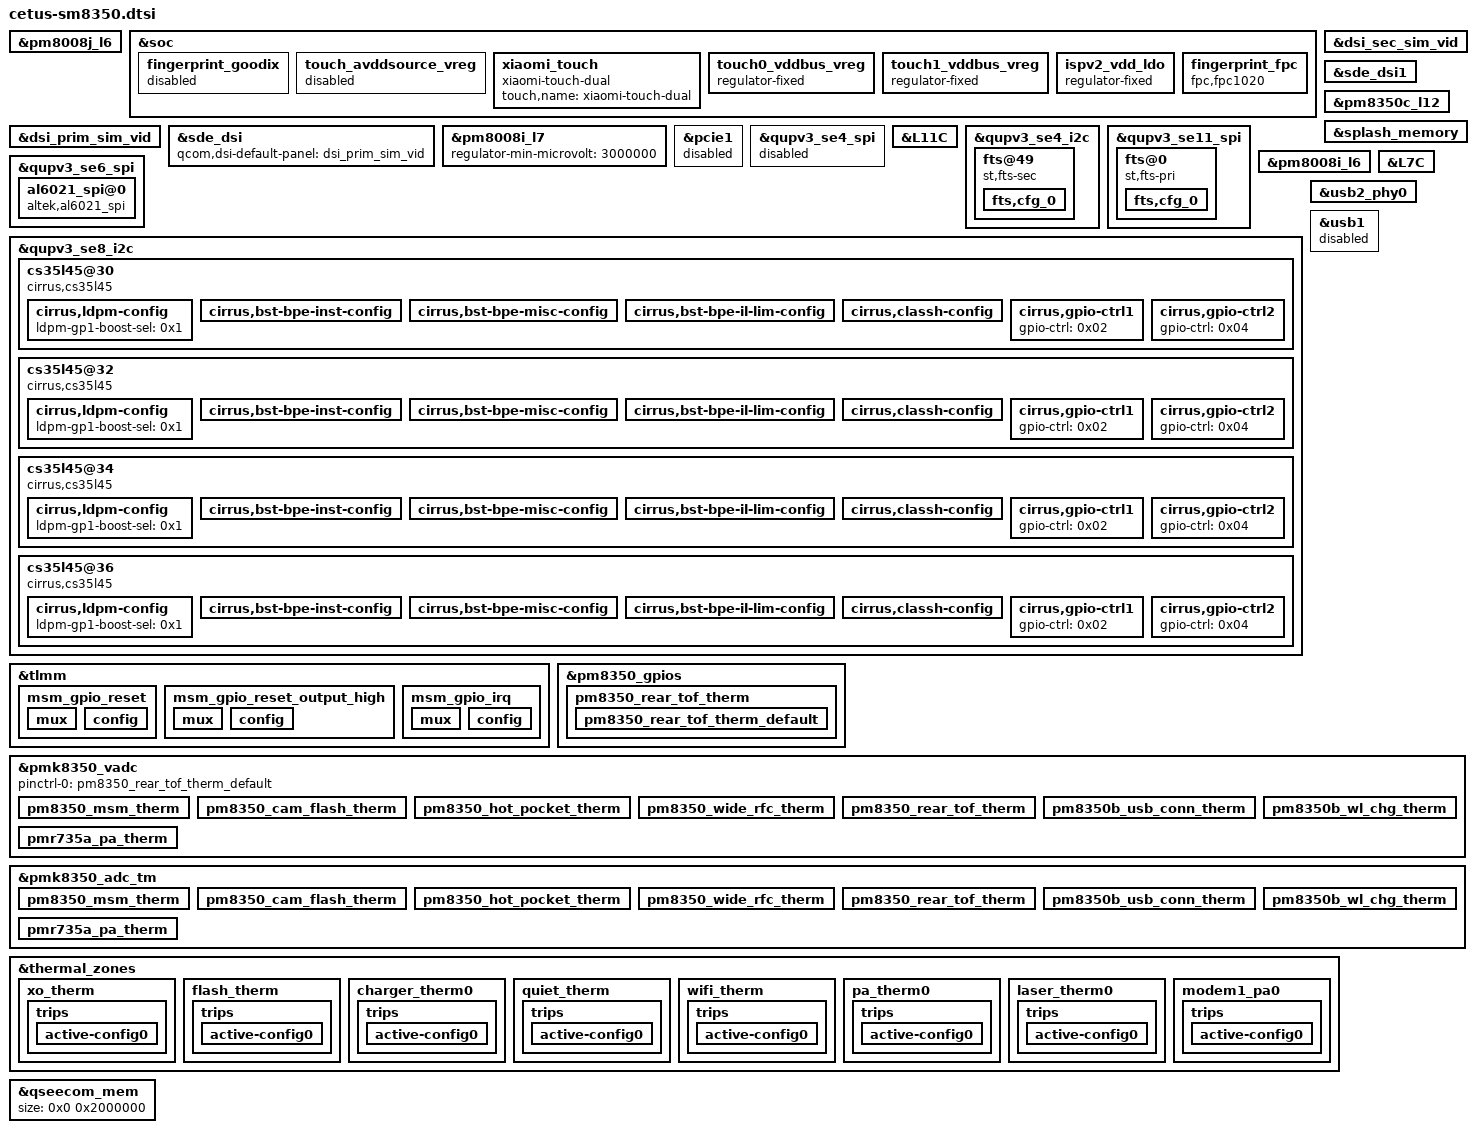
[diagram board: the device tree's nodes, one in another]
/*
this file is for attribution only of star
And public attribution of xiaomi platforms(like venus and so and)
*/

#include "cetus-pinctrl.dtsi"
#include "xiaomi-sm8350-common.dtsi"
#include "cetus-audio-overlay.dtsi"
#include "camera/cetus-sm8350-camera-sensor.dtsi"
#include <dt-bindings/clock/qcom,camcc-lahaina.h>

&pm8008j_l6 {
	reg = <0x4500>;
	regulator-name = "pm8008j_l6";
	regulator-min-microvolt = <1800000>;
	regulator-max-microvolt = <1800000>;
	qcom,min-dropout-voltage = <70000>;
};

&soc {
	fingerprint_goodix {
		status = "disable";
	};

	touch_avddsource_vreg {
		status = "disable";
	};

	xiaomi_touch {
		compatible = "xiaomi-touch-dual";
		status = "ok";
		touch,name = "xiaomi-touch-dual";
	};

	touch0_vddbus_vreg: touch0_vddbus_vreg {
		compatible = "regulator-fixed";
		regulator-name = "touch0_vddbus_vreg";
		enable-active-high;
		regulator-boot-on;
		gpio = <&tlmm 12 0>;
	};

	touch1_vddbus_vreg: touch1_vddbus_vreg {
		compatible = "regulator-fixed";
		regulator-name = "touch1_vddbus_vreg";
		enable-active-high;
		regulator-boot-on;
		gpio = <&tlmm 13 0>;
	};

	ispv2_vdd_ldo: ispv2_vdd_ldo{
		compatible = "regulator-fixed";
		regulator-name = "ispv2_vdd_ldo";
		regulator-min-microvolt = <900000>;
		regulator-max-microvolt = <900000>;
		regulator-enable-ramp-delay = <100>;
		enable-active-high;
		gpio = <&tlmm 166 0>;
		vin-supply = <&pm8350_s11>;
	};

	fingerprint_fpc {
		status = "ok";
		compatible = "fpc,fpc1020";
		interrupt-parent = <&tlmm>;
		interrupts = <38 0x0>;
		fpc,gpio_rst    = <&tlmm 39 0x0>;
		fpc,gpio_irq    = <&tlmm 38 0x0>;
		fpc,gpio_vdd1v8 = <&tlmm 6  0x0>;
		fp_vdd_vreg-supply = <&L7C>;
		pinctrl-names = "fpc1020_reset_reset",
						"fpc1020_reset_active",
						"fpc1020_irq_active";

		pinctrl-0 = <&msm_gpio_reset>;
		pinctrl-1 = <&msm_gpio_reset_output_high>;
		pinctrl-2 = <&msm_gpio_irq>;
	};
};

&dsi_prim_sim_vid {
	qcom,panel-supply-entries = <&dsi_panel_pwr_supply_prim>;
	qcom,mdss-dsi-bl-pmic-control-type = "bl_ctrl_dcs";
	qcom,platform-reset-gpio = <&tlmm 24 0>;
};

&dsi_sec_sim_vid {
	qcom,panel-sec-supply-entries = <&dsi_panel_pwr_supply_sec>;
	qcom,mdss-dsi-sec-bl-pmic-control-type = "bl_ctrl_dcs";
	qcom,platform-sec-reset-gpio = <&tlmm 74 0>;
};

&sde_dsi {
	qcom,dsi-default-panel = <&dsi_prim_sim_vid>;
};

&sde_dsi1 {
	sec-vddio-supply = <&L2C>;
	sec-vdd-supply = <&L7I>;
	qcom,dsi-default-panel = <&dsi_sec_sim_vid>;
};

&pm8008i_l7 {
	regulator-min-microvolt = <3000000>;
};

&pm8350c_l12 {
	regulator-min-microvolt = <1900000>;
	regulator-max-microvolt = <1900000>;
	qcom,init-voltage = <1900000>;
};

&splash_memory {
	reg = <0x0 0xea600000 0x0 0x0119c000>,
		<0x0 0xeb79c000 0x0 0x0815000>;
};

&pcie1 {
	status = "disabled";
};

&qupv3_se4_spi {
	status = "disabled";
};

&L11C {
		regulator-always-on;
		qcom,init-voltage = <3008000>;
};


&qupv3_se4_i2c {
	#address-cells = <1>;
	#size-cells = <0>;

	status = "ok";
	fts@49 {
		status = "ok";
		compatible = "st,fts-sec";
		reg = <0x49>;
		interrupt-parent = <&tlmm>;
		interrupts = <99 0x2008>;
		pinctrl-names = "pmx_ts1_active", "pmx_ts1_suspend";
		pinctrl-0 = <&ts1_active>;
		pinctrl-1 = <&ts1_int_suspend &ts1_reset_suspend>;
		avdd-supply = <&L11C>;
		vdd-supply = <&touch1_vddbus_vreg>;
		fts,pwr-reg-name = "avdd";
		fts,bus-reg-name = "vdd";
		fts,irq-gpio = <&tlmm 99 0x2008>;
		fts,irq-gpio-name = "fts1_irq";
		fts,reset-gpio-enable;
		fts,reset-gpio = <&tlmm 97 0x00>;
		fts,reset-gpio-name = "fts1_rst";
		fts,irq-flags = <0x2008>; /* IRQF_ONESHOT | IRQF_TRIGGER_LOW */
		fts,x-max = <840>;
		fts,y-max = <2520>;
		fts,fod-lx = <421>;
		fts,fod-ly = <1788>;
		fts,fod-x-size = <238>;
		fts,fod-y-size = <238>;
		fts,default-fw-name = "st_fts_j18_sec.ftb";
		fts,config-array-size = <1>;
		/*fts,support-fod;*/
		fts,touch-up-threshold-min = <40>;
		fts,touch-up-threshold-max = <120>;
		fts,touch-up-threshold-def = <80>;
		fts,touch-tolerance-min = <5>;
		fts,touch-tolerance-max = <35>;
		fts,touch-tolerance-def = <25>;
		fts,touch-idletime-min = <0>;
		fts,touch-idletime-max = <12750>;
		fts,touch-idletime-def = <12450>;
		/*edge filter rects in gamemode*/
		fts,cornerfilter-area-step1 = <150>;
		fts,cornerfilter-area-step2 = <280>;
		fts,cornerfilter-area-step3 = <400>;
		fts,touch-deadzone-filter-ver = <2 0 0 0 0 0 0 0
										2 1 0 0 0 0 0 0
										2 2 0 0 0 0 0 0
										2 3 0 0 0 0 0 0>;
		fts,touch-deadzone-filter-hor = <2 0 0 0 0 0 0 0
										2 1 0 0 0 0 0 0
										2 2 0 0 0 0 0 0
										2 3 0 0 0 0 0 0>;
		fts,touch-edgezone-filter-ver = <1 0 0 0 0 0 0 0
										1 1 0 0 0 0 0 0
										1 2 0 0 30 2519 0 0
										1 3 809 0 839 2519 0 0>;
		fts,touch-edgezone-filter-hor = <1 0 0 0 839 30 0 0
										1 1 0 2489 839 2519 0 0
										1 2 0 0 0 0 0 0
										1 3 0 0 0 0 0 0>;
		fts,touch-cornerzone-filter-ver = <0 0 0 0 0 0 0 0
										0 1 0 0 0 0 0 0
										0 2 0 2209 114 2519 0 0
										0 3 725 2209 839 2519 0 0>;
		fts,touch-cornerzone-filter-hor1 = <0 0 0 0 114 310 0 0
										0 1 0 0 0 0 0 0
										0 2 0 2209 114 2519 0 0
										0 3 0 0 0 0 0 0>;
		fts,touch-cornerzone-filter-hor2 = <0 0 0 0 0 0 0 0
										0 1 725 0 839 310 0 0
										0 2 0 0 0 0 0 0
										0 3 725 2209 839 2519 0 0>;
		fts,cfg_0 {
			fts,tp-vendor = <0x38>;
			fts,fw-name = "st_fts_j18_sec.ftb";
			fts,limit-name = "stm_fts_production_limits_j18_sec.csv";
		};
	};
};

&qupv3_se11_spi {
	status = "ok";
	fts@0 {
		status = "ok";
		compatible = "st,fts-pri";
		reg = <0x0>;
		interrupt-parent = <&tlmm>;
		interrupts = <23 0x2008>;
		pinctrl-names = "pmx_ts0_active", "pmx_ts0_suspend";
		pinctrl-0 = <&ts0_active>;
		pinctrl-1 = <&ts0_int_suspend &ts0_reset_suspend>;
		avdd-supply = <&L3C>;
		vdd-supply = <&touch0_vddbus_vreg>;
		fts,pwr-reg-name = "avdd";
		fts,bus-reg-name = "vdd";
		fts,irq-gpio = <&tlmm 23 0x2008>;
		fts,irq-gpio-name = "fts0_irq";
		fts,reset-gpio-enable;
		fts,reset-gpio = <&tlmm 22 0x00>;
		fts,reset-gpio-name = "fts0_rst";
		fts,irq-flags = <0x2008>; /* IRQF_ONESHOT | IRQF_TRIGGER_LOW */
		fts,x-max = <1860>;
		fts,y-max = <2480>;
		fts,fod-lx = <421>;
		fts,fod-ly = <1788>;
		fts,fod-x-size = <238>;
		fts,fod-y-size = <238>;
		spi-max-frequency = <7000000>;
		fts,default-fw-name = "st_fts_j18_pri.ftb";
		fts,config-array-size = <1>;
		/*fts,support-fod;*/
		fts,touch-up-threshold-min = <40>;
		fts,touch-up-threshold-max = <120>;
		fts,touch-up-threshold-def = <80>;
		fts,touch-tolerance-min = <5>;
		fts,touch-tolerance-max = <35>;
		fts,touch-tolerance-def = <25>;
		fts,touch-idletime-min = <0>;
		fts,touch-idletime-max = <12750>;
		fts,touch-idletime-def = <12450>;
		/*edge filter rects in gamemode*/
		fts,cornerfilter-area-step1 = <100>;
		fts,cornerfilter-area-step2 = <280>;
		fts,cornerfilter-area-step3 = <400>;
		fts,touch-deadzone-filter-ver = <2 0 0 0 0 0 0 0
										2 1 0 0 0 0 0 0
										2 2 0 0 0 0 0 0
										2 3 0 0 0 0 0 0>;
		fts,touch-deadzone-filter-hor = <2 0 0 0 0 0 0 0
										2 1 0 0 0 0 0 0
										2 2 0 0 0 0 0 0
										2 3 0 0 0 0 0 0>;
		fts,touch-edgezone-filter-ver = <1 0 0 0 0 0 0 0
										1 1 0 0 0 0 0 0
										1 2 0 0 60 2479 0 0
										1 3 1799 0 1859 2479 0 0>;
		fts,touch-edgezone-filter-hor = <1 0 0 0 1859 60 0 0
										1 1 0 2419 1859 2479 0 0
										1 2 0 0 60 2479 0 0
										1 3 1799 0 1799 2479 0 0>;
		fts,touch-cornerzone-filter-ver = <0 0 0 0 0 0 0 0
										0 1 0 0 0 0 0 0
										0 2 0 2079 250 2479 0 0
										0 3 1459 2079 1859 2479 0 0>;
		fts,touch-cornerzone-filter-hor1 = <0 0 0 0 280 280 0 0
										0 1 0 0 0 0 0 0
										0 2 0 2199 280 2479 0 0
										0 3 0 0 0 0 0 0>;
		fts,touch-cornerzone-filter-hor2 = <0 0 0 0 0 0 0 0
										0 1 1579 0 1859 280 0 0
										0 2 0 0 0 0 0 0
										0 3 1579 2199 1859 2479 0 0>;
		fts,cfg_0 {
			fts,tp-vendor = <0x38>;
			fts,fw-name = "st_fts_j18_pri.ftb";
			fts,limit-name = "stm_fts_production_limits_j18_pri.csv";
		};
	};
};

&pm8008i_l6 {
	reg = <0x4500>;
	regulator-name = "pm8008i_l6";
	regulator-min-microvolt = <1800000>;
	regulator-max-microvolt = <1800000>;
	qcom,min-dropout-voltage = <200000>;
};

&qupv3_se6_spi {
       status = "ok";
       al6021_spi@0 {
		compatible = "altek,al6021_spi";
		reg = <0>;
		spi-max-frequency = <50000000>;
		irq-gpio = <&tlmm 165 0x00>;
		reset-gpio = <&tlmm 164 0x0>;
		cs-gpio = <&tlmm 31 0x0>;
		ispv2_vcc-supply = <&pm8008i_l6>;
		ispv2_vdd-supply = <&ispv2_vdd_ldo>;
		ispv2_clk-supply = <&cam_cc_titan_top_gdsc>;
		regulator-names = "ispv2_vcc", "ispv2_vdd", "ispv2_clk";
		rgltr-min-voltage = <1800000 900000 0>;
		rgltr-max-voltage = <1800000 900000 0>;
		rgltr-load-current = <100000 500000 0>;
		pinctrl-names = "ispv2_default", "ispv2_suspend";
		pinctrl-0 = <&cam_sensor_mclk4_active>;
		pinctrl-1 = <&cam_sensor_mclk4_suspend>;
		status = "ok";
		clocks = <&clock_camcc CAM_CC_MCLK4_CLK>;
		clock-names = "ispv2_clk";
		clock-cntl-level = "turbo";
		clock-rates = <19200000>;
       };
};

&qupv3_se8_i2c {
	status = "ok";
	cs35l45@30 {
		status = "ok";
		compatible = "cirrus,cs35l45";
		reset-gpios = <&tlmm 25 0>;
		reg = <0x30>;
		VA-supply = <&pm8008j_l6>;
		interrupt-parent = <&tlmm>;
		interrupts = <26 0x2008>;
		pinctrl-names = "default";
		pinctrl-0 = <&cirrus_irq_default_30>;
		cirrus,asp-sdout-hiz-ctrl = <3>;
		cirrus,right-channel-amp;
		sound-name-prefix = "MT";
		cirrus,dsp-part-name = "cs35l45-MT";
		cirrus,fast-switch = "MT-music.txt", "MT-voice.txt", "MT-voip.txt", "MT-misc.txt";
		cirrus,sync-num-slaves = <0x3>;
		cirrus,sync-id = <0x0>;
		cirrus,ldpm-config {
			ldpm-gp1-boost-sel = <0x1>;
		};
		cirrus,bst-bpe-inst-config {
			bst-bpe-inst-thld = <0x1E 0x30 0x46 0x5A 0>;
			bst-bpe-inst-ilim = <0 0x00 0x04 0x14 0x3C>;
			bst-bpe-inst-ss-ilim = <0 0x00 0x04 0x08 0x1C>;
			bst-bpe-inst-atk-rate = <0 0x03 0x06 0x06 0>;
			bst-bpe-inst-hold-time = <0x02 0x02 0x02 0x02 0>;
			bst-bpe-inst-rls-rate = <0x06 0x06 0x06 0x06 0>;
		};
		cirrus,bst-bpe-misc-config {
			bst-bpe-inst-inf-hold-rls = <0x0>;
			bst-bpe-il-lim-mode = <0x0>;
			bst-bpe-out-opmode-sel = <0x0>;
			bst-bpe-inst-l3-byp = <0x1>;
			bst-bpe-inst-l2-byp = <0x1>;
			bst-bpe-inst-l1-byp = <0x0>;
			bst-bpe-filt-sel = <0x0>;
		};
		cirrus,bst-bpe-il-lim-config {
			bst-bpe-il-lim-thld-hyst = <0x0>;
			bst-bpe-il-lim-thld-del1 = <0x00>;
			bst-bpe-il-lim-thld-del2 = <0x00>;
			bst-bpe-il-lim1-thld = <0x3C>;
		};
		cirrus,classh-config {
			ch-ovb-thld1 = <0x5a>;
			ch-ovb-thlddelta = <0xc8>;
			ch-ovb-ratio = <0x1>;
			ch-thld1-offset = <0x23>;
		};
		cirrus,gpio-ctrl1 {
			gpio-ctrl = <0x02>;
		};
		cirrus,gpio-ctrl2 {
			gpio-ctrl = <0x04>;
		};
	};
	cs35l45@32 {
		compatible = "cirrus,cs35l45";
		reset-gpios = <&tlmm 178 0>;
		reg = <0x32>;
		VA-supply = <&pm8008j_l6>;
		interrupt-parent = <&tlmm>;
		interrupts = <179 0x2008>;
		pinctrl-names = "default";
		pinctrl-0 = <&cirrus_irq_default_32>;
		cirrus,asp-sdout-hiz-ctrl = <3>;
		sound-name-prefix = "MD";
		cirrus,dsp-part-name = "cs35l45-MD";
		cirrus,fast-switch = "MD-music.txt", "MD-voice.txt", "MD-voip.txt", "MD-misc.txt";
		cirrus,sync-num-slaves = <0x3>;
		cirrus,sync-id = <0x1>;
		cirrus,ldpm-config {
			ldpm-gp1-boost-sel = <0x1>;
		};
		cirrus,bst-bpe-inst-config {
			bst-bpe-inst-thld = <0x1E 0x31 0x46 0x5A 0>;
			bst-bpe-inst-ilim = <0 0x00 0x04 0x14 0x3C>;
			bst-bpe-inst-ss-ilim = <0 0x00 0x04 0x08 0x1C>;
			bst-bpe-inst-atk-rate = <0 0x03 0x06 0x06 0>;
			bst-bpe-inst-hold-time = <0x02 0x02 0x02 0x02 0>;
			bst-bpe-inst-rls-rate = <0x06 0x06 0x06 0x06 0>;
		};
		cirrus,bst-bpe-misc-config {
			bst-bpe-inst-inf-hold-rls = <0x0>;
			bst-bpe-il-lim-mode = <0x0>;
			bst-bpe-out-opmode-sel = <0x0>;
			bst-bpe-inst-l3-byp = <0x1>;
			bst-bpe-inst-l2-byp = <0x1>;
			bst-bpe-inst-l1-byp = <0x0>;
			bst-bpe-filt-sel = <0x0>;
		};
		cirrus,bst-bpe-il-lim-config {
			bst-bpe-il-lim-thld-hyst = <0x0>;
			bst-bpe-il-lim-thld-del1 = <0x00>;
			bst-bpe-il-lim-thld-del2 = <0x00>;
			bst-bpe-il-lim1-thld = <0x3C>;
		};
		cirrus,classh-config {
			ch-ovb-thld1 = <0x5a>;
			ch-ovb-thlddelta = <0xc8>;
			ch-ovb-ratio = <0x1>;
			ch-thld1-offset = <0x23>;
		};
		cirrus,gpio-ctrl1 {
			gpio-ctrl = <0x02>;
		};
		cirrus,gpio-ctrl2 {
			gpio-ctrl = <0x04>;
		};
	};
	cs35l45@34 {
		status = "ok";
		compatible = "cirrus,cs35l45";
		reset-gpios = <&tlmm 15 0>;
		reg = <0x34>;
		VA-supply = <&pm8008j_l6>;
		interrupt-parent = <&tlmm>;
		interrupts = <44 0x2008>;
		pinctrl-names = "default";
		pinctrl-0 = <&cirrus_irq_default_34>;
		cirrus,asp-sdout-hiz-ctrl = <3>;
		cirrus,right-channel-amp;
		sound-name-prefix = "FT";
		cirrus,dsp-part-name = "cs35l45-FT";
		cirrus,fast-switch = "FT-music.txt", "FT-voice.txt", "FT-voip.txt", "FT-misc.txt";
		cirrus,sync-num-slaves = <0x3>;
		cirrus,sync-id = <0x2>;
		cirrus,ldpm-config {
			ldpm-gp1-boost-sel = <0x1>;
		};
		cirrus,bst-bpe-inst-config {
			bst-bpe-inst-thld = <0x1E 0x28 0x46 0x5A 0>;
			bst-bpe-inst-ilim = <0 0x00 0x04 0x14 0x3C>;
			bst-bpe-inst-ss-ilim = <0 0x00 0x04 0x08 0x1C>;
			bst-bpe-inst-atk-rate = <0 0x03 0x06 0x06 0>;
			bst-bpe-inst-hold-time = <0x02 0x02 0x02 0x02 0>;
			bst-bpe-inst-rls-rate = <0x06 0x06 0x06 0x06 0>;
		};
		cirrus,bst-bpe-misc-config {
			bst-bpe-inst-inf-hold-rls = <0x0>;
			bst-bpe-il-lim-mode = <0x0>;
			bst-bpe-out-opmode-sel = <0x0>;
			bst-bpe-inst-l3-byp = <0x1>;
			bst-bpe-inst-l2-byp = <0x1>;
			bst-bpe-inst-l1-byp = <0x0>;
			bst-bpe-filt-sel = <0x0>;
		};
		cirrus,bst-bpe-il-lim-config {
			bst-bpe-il-lim-thld-hyst = <0x0>;
			bst-bpe-il-lim-thld-del1 = <0x00>;
			bst-bpe-il-lim-thld-del2 = <0x00>;
			bst-bpe-il-lim1-thld = <0x3C>;
		};
		cirrus,classh-config {
			ch-ovb-thld1 = <0x5a>;
			ch-ovb-thlddelta = <0xc8>;
			ch-ovb-ratio = <0x1>;
			ch-thld1-offset = <0x23>;
		};
		cirrus,gpio-ctrl1 {
			gpio-ctrl = <0x02>;
		};
		cirrus,gpio-ctrl2 {
			gpio-ctrl = <0x04>;
		};
	};
	cs35l45@36 {
		compatible = "cirrus,cs35l45";
		reset-gpios = <&tlmm 42 0>;
		reg = <0x36>;
		VA-supply = <&pm8008j_l6>;
		interrupt-parent = <&tlmm>;
		interrupts = <79 0x2008>;
		pinctrl-names = "default";
		pinctrl-0 = <&cirrus_irq_default_36>;
		cirrus,asp-sdout-hiz-ctrl = <3>;
		sound-name-prefix = "FD";
		cirrus,dsp-part-name = "cs35l45-FD";
		cirrus,fast-switch = "FD-music.txt", "FD-voice.txt", "FD-voip.txt", "FD-misc.txt";
		cirrus,sync-num-slaves = <0x3>;
		cirrus,sync-id = <0x3>;
		cirrus,ldpm-config {
			ldpm-gp1-boost-sel = <0x1>;
		};
		cirrus,bst-bpe-inst-config {
			bst-bpe-inst-thld = <0x1E 0x28 0x46 0x5A 0>;
			bst-bpe-inst-ilim = <0 0x00 0x04 0x14 0x3C>;
			bst-bpe-inst-ss-ilim = <0 0x00 0x04 0x08 0x1C>;
			bst-bpe-inst-atk-rate = <0 0x03 0x06 0x06 0>;
			bst-bpe-inst-hold-time = <0x02 0x02 0x02 0x02 0>;
			bst-bpe-inst-rls-rate = <0x06 0x06 0x06 0x06 0>;
		};
		cirrus,bst-bpe-misc-config {
			bst-bpe-inst-inf-hold-rls = <0x0>;
			bst-bpe-il-lim-mode = <0x0>;
			bst-bpe-out-opmode-sel = <0x0>;
			bst-bpe-inst-l3-byp = <0x1>;
			bst-bpe-inst-l2-byp = <0x1>;
			bst-bpe-inst-l1-byp = <0x0>;
			bst-bpe-filt-sel = <0x0>;
		};
		cirrus,bst-bpe-il-lim-config {
			bst-bpe-il-lim-thld-hyst = <0x0>;
			bst-bpe-il-lim-thld-del1 = <0x00>;
			bst-bpe-il-lim-thld-del2 = <0x00>;
			bst-bpe-il-lim1-thld = <0x3C>;
		};
		cirrus,classh-config {
			ch-ovb-thld1 = <0x5a>;
			ch-ovb-thlddelta = <0xc8>;
			ch-ovb-ratio = <0x1>;
			ch-thld1-offset = <0x23>;
		};
		cirrus,gpio-ctrl1 {
			gpio-ctrl = <0x02>;
		};
		cirrus,gpio-ctrl2 {
			gpio-ctrl = <0x04>;
		};
	};
};

&L7C {
	regulator-min-microvolt = <3300000>;
	regulator-max-microvolt = <3300000>;
	qcom,init-voltage = <3300000>;
};

&tlmm {
		/* FP_RESET_N */
	msm_gpio_reset: msm_gpio_reset {
		mux {
			pins = "gpio39";
			function = "gpio";
		};
		config {
			pins = "gpio39";
			drive-strength = <2>;
			bias-disable;
			output-low;
		};
	};
		/* FP_RESET_N, state device active*/
	msm_gpio_reset_output_high: msm_gpio_reset_output_high {
		mux {
			pins = "gpio39";
			function = "gpio";
		};
		config {
			pins = "gpio39";
			drive-strength = <2>;
			bias-disable;
			output-high;
		};
	};
		/* FP_INT_N */
	msm_gpio_irq: msm_gpio_irq {
		mux {
			pins = "gpio38";
			function = "gpio";
		};
		config {
			pins = "gpio38";
			drive-strength = <2>;
			bias-pull-down;
		};
	};
};

&pm8350_gpios {
	pm8350_rear_tof_therm {
		pm8350_rear_tof_therm_default: pm8350_rear_tof_therm_default {
			pins = "gpio1";
			bias-high-impedance;
		};
	};
};


&usb2_phy0 {
	qcom,param-override-seq =
	<0xe6 0x6c	/* override_x0 */
	 0x0b 0x70	/* override_x1 */
	 0x04 0x74>;	/* override x2 */
};

&usb1 {
	status = "disabled";
};

&pmk8350_vadc {
	pinctrl-names = "default";
	pinctrl-0 = <&pm8350_rear_tof_therm_default>;

	pm8350_msm_therm {
		reg = <PM8350_ADC7_AMUX_THM1_100K_PU>;
		label = "pm8350_msm_therm";
		qcom,ratiometric;
		qcom,hw-settle-time = <200>;
		qcom,pre-scaling = <1 1>;
	};

	pm8350_cam_flash_therm {
		reg = <PM8350_ADC7_AMUX_THM2_100K_PU>;
		label = "pm8350_cam_flash_therm";
		qcom,ratiometric;
		qcom,hw-settle-time = <200>;
		qcom,pre-scaling = <1 1>;
	};

	pm8350_hot_pocket_therm {
		reg = <PM8350_ADC7_AMUX_THM3_100K_PU>;
		label = "pm8350_hot_pocket_therm";
		qcom,ratiometric;
		qcom,hw-settle-time = <200>;
		qcom,pre-scaling = <1 1>;
	};

	pm8350_wide_rfc_therm {
		reg = <PM8350_ADC7_AMUX_THM4_100K_PU>;
		label = "pm8350_wide_rfc_therm";
		qcom,ratiometric;
		qcom,hw-settle-time = <200>;
		qcom,pre-scaling = <1 1>;
	};

	pm8350_rear_tof_therm {
		reg = <PM8350_ADC7_AMUX_THM5_100K_PU>;
		label = "pm8350_rear_tof_therm";
		qcom,ratiometric;
		qcom,hw-settle-time = <200>;
		qcom,pre-scaling = <1 1>;
	};

	pm8350b_usb_conn_therm {
		reg = <PMR735A_ADC7_GPIO1_100K_PU>;
		label = "pm8350b_usb_conn_therm";
		qcom,ratiometric;
		qcom,hw-settle-time = <200>;
		qcom,pre-scaling = <1 1>;
	};

	pm8350b_wl_chg_therm {
		reg = <PMK8350_ADC7_AMUX_THM1_100K_PU>;
		label = "pm8350b_wl_chg_therm";
		qcom,ratiometric;
		qcom,hw-settle-time = <200>;
		qcom,pre-scaling = <1 1>;
	};

	pmr735a_pa_therm {
		reg = <PMR735A_ADC7_GPIO3_100K_PU>;
		label = "pmr735a_pa_therm";
		qcom,ratiometric;
		qcom,hw-settle-time = <200>;
		qcom,pre-scaling = <1 1>;
	};
};

&pmk8350_adc_tm {
	io-channels = <&pmk8350_vadc PM8350_ADC7_AMUX_THM1_100K_PU>,
			<&pmk8350_vadc PM8350_ADC7_AMUX_THM2_100K_PU>,
			<&pmk8350_vadc PM8350_ADC7_AMUX_THM3_100K_PU>,
			<&pmk8350_vadc PM8350_ADC7_AMUX_THM4_100K_PU>,
			<&pmk8350_vadc PM8350_ADC7_AMUX_THM5_100K_PU>,
			<&pmk8350_vadc PMR735A_ADC7_GPIO1_100K_PU>,
			<&pmk8350_vadc PMK8350_ADC7_AMUX_THM1_100K_PU>,
			<&pmk8350_vadc PMR735A_ADC7_GPIO3_100K_PU>;

	pm8350_msm_therm {
		reg = <PM8350_ADC7_AMUX_THM1_100K_PU>;
		qcom,ratiometric;
		qcom,hw-settle-time = <200>;
	};

	pm8350_cam_flash_therm {
		reg = <PM8350_ADC7_AMUX_THM2_100K_PU>;
		qcom,ratiometric;
		qcom,hw-settle-time = <200>;
	};

	pm8350_hot_pocket_therm {
		reg = <PM8350_ADC7_AMUX_THM3_100K_PU>;
		qcom,ratiometric;
		qcom,hw-settle-time = <200>;
	};

	pm8350_wide_rfc_therm {
		reg = <PM8350_ADC7_AMUX_THM4_100K_PU>;
		qcom,ratiometric;
		qcom,hw-settle-time = <200>;
	};

	pm8350_rear_tof_therm {
		reg = <PM8350_ADC7_AMUX_THM5_100K_PU>;
		qcom,ratiometric;
		qcom,hw-settle-time = <200>;
	};

	pm8350b_usb_conn_therm {
		reg = <PMR735A_ADC7_GPIO1_100K_PU>;
		qcom,ratiometric;
		qcom,hw-settle-time = <200>;
	};

	pm8350b_wl_chg_therm {
		reg = <PMK8350_ADC7_AMUX_THM1_100K_PU>;
		qcom,ratiometric;
		qcom,hw-settle-time = <200>;
	};

	pmr735a_pa_therm {
		reg = <PMR735A_ADC7_GPIO3_100K_PU>;
		qcom,ratiometric;
		qcom,hw-settle-time = <200>;
	};
};

&thermal_zones {
        xo_therm {
                polling-delay-passive = <0>;
                polling-delay = <0>;
                thermal-governor = "user_space";
                thermal-sensors = <&pmk8350_adc_tm PMK8350_ADC7_AMUX_THM1_100K_PU>;
                wake-capable-sensor;
                trips {
                        active-config0 {
                                temperature = <125000>;
                                hysteresis = <1000>;
                                type = "passive";
                        };
                };
        };

        flash_therm {
                polling-delay-passive = <0>;
                polling-delay = <0>;
                thermal-governor = "user_space";
                thermal-sensors = <&pmk8350_adc_tm PM8350_ADC7_AMUX_THM2_100K_PU>;
                wake-capable-sensor;
                trips {
                        active-config0 {
                                temperature = <125000>;
                                hysteresis = <1000>;
                                type = "passive";
                        };
                };
        };

        charger_therm0 {
                polling-delay-passive = <0>;
                polling-delay = <0>;
                thermal-governor = "user_space";
                thermal-sensors = <&pmk8350_adc_tm PM8350_ADC7_AMUX_THM3_100K_PU>;
                wake-capable-sensor;
                trips {
                        active-config0 {
                                temperature = <125000>;
                                hysteresis = <1000>;
                                type = "passive";
                        };
                };
        };

        quiet_therm {
                polling-delay-passive = <0>;
                polling-delay = <0>;
                thermal-governor = "user_space";
                thermal-sensors = <&pmk8350_adc_tm PM8350_ADC7_AMUX_THM4_100K_PU>;
                wake-capable-sensor;
                trips {
                        active-config0 {
                                temperature = <125000>;
                                hysteresis = <1000>;
                                type = "passive";
                        };
                };
        };

        wifi_therm {
                polling-delay-passive = <0>;
                polling-delay = <0>;
                thermal-governor = "user_space";
                thermal-sensors = <&pmk8350_adc_tm PM8350_ADC7_AMUX_THM5_100K_PU>;
                wake-capable-sensor;
                trips {
                        active-config0 {
                                temperature = <125000>;
                                hysteresis = <1000>;
                                type = "passive";
                        };
                };
        };

        pa_therm0 {
                polling-delay-passive = <0>;
                polling-delay = <0>;
                thermal-governor = "user_space";
                thermal-sensors = <&pmk8350_adc_tm PMR735A_ADC7_GPIO1_100K_PU>;
                wake-capable-sensor;
                trips {
                        active-config0 {
                                temperature = <125000>;
                                hysteresis = <1000>;
                                type = "passive";
                        };
                };
        };

        laser_therm0 {
                polling-delay-passive = <0>;
                polling-delay = <0>;
                thermal-governor = "user_space";
                thermal-sensors = <&pmk8350_adc_tm PM8350_ADC7_AMUX_THM1_100K_PU>;
                wake-capable-sensor;
                trips {
                        active-config0 {
                                temperature = <125000>;
                                hysteresis = <1000>;
                                type = "passive";
                        };
                };
        };

        modem1_pa0 {
                polling-delay-passive = <0>;
                polling-delay = <0>;
                thermal-governor = "user_space";
                thermal-sensors = <&pmk8350_adc_tm PMR735A_ADC7_GPIO3_100K_PU>;
                wake-capable-sensor;
                trips {
                        active-config0 {
                                temperature = <125000>;
                                hysteresis = <1000>;
                                type = "passive";
                        };
                };
        };
};

&qseecom_mem {
	size = <0x0 0x2000000>;
};
